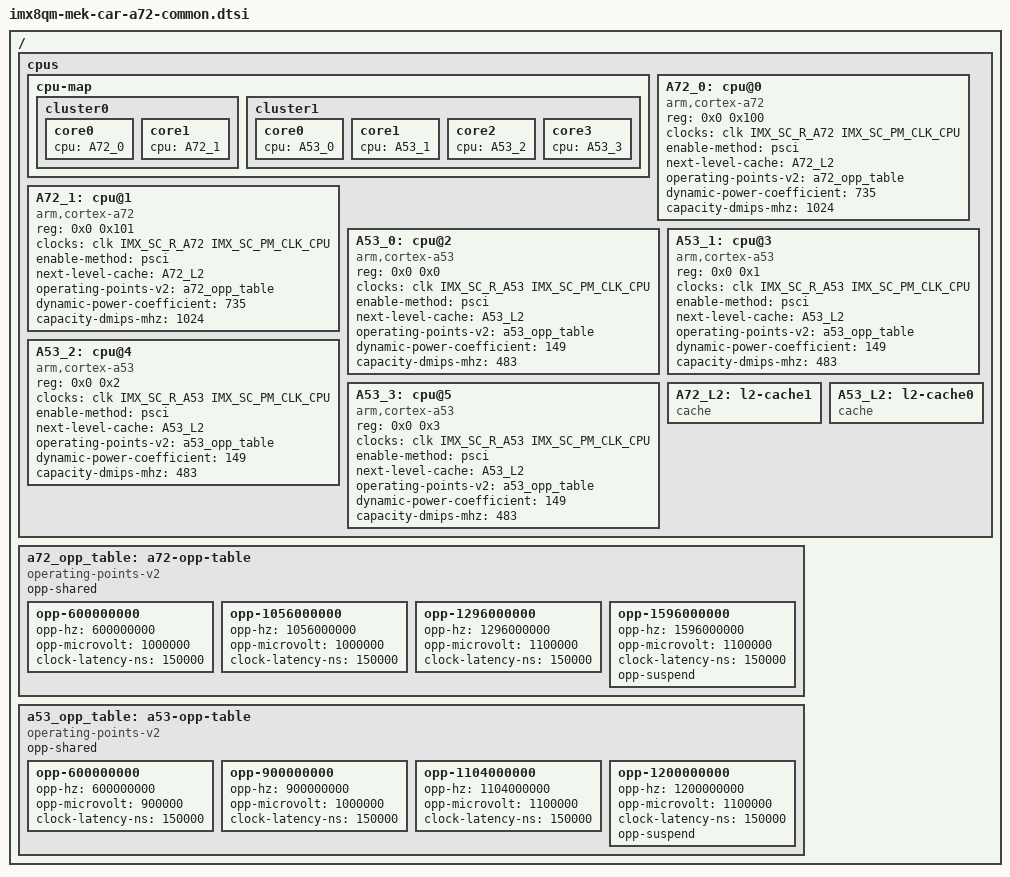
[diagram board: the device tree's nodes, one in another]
/*
 * Copyright 2020 NXP
 *
 * This program is free software; you can redistribute it and/or
 * modify it under the terms of the GNU General Public License
 * as published by the Free Software Foundation; either version 2
 * of the License, or (at your option) any later version.
 *
 * This program is distributed in the hope that it will be useful,
 * but WITHOUT ANY WARRANTY; without even the implied warranty of
 * MERCHANTABILITY or FITNESS FOR A PARTICULAR PURPOSE.  See the
 * GNU General Public License for more details.
 */

/ {
    /delete-node/ cpus;
};

/* copied from imx8qm.dtsi */
/ {
	cpus: cpus {
		#address-cells = <2>;
		#size-cells = <0>;

		cpu-map {
			cluster0 {
				core0 {
					cpu = <&A72_0>;
				};
				core1 {
					cpu = <&A72_1>;
				};
			};

			cluster1 {
				core0 {
					cpu = <&A53_0>;
				};
				core1 {
					cpu = <&A53_1>;
				};
				core2 {
					cpu = <&A53_2>;
				};
				core3 {
					cpu = <&A53_3>;
				};
			};
		};

		A72_0: cpu@0 {
			device_type = "cpu";
			compatible = "arm,cortex-a72", "arm,armv8";
			reg = <0x0 0x100>;
			clocks = <&clk IMX_SC_R_A72 IMX_SC_PM_CLK_CPU>;
			enable-method = "psci";
			next-level-cache = <&A72_L2>;
			operating-points-v2 = <&a72_opp_table>;
			#cooling-cells = <2>;
			dynamic-power-coefficient = <735>;
			capacity-dmips-mhz = <1024>;
		};

		A72_1: cpu@1 {
			device_type = "cpu";
			compatible = "arm,cortex-a72", "arm,armv8";
			reg = <0x0 0x101>;
			clocks = <&clk IMX_SC_R_A72 IMX_SC_PM_CLK_CPU>;
			enable-method = "psci";
			next-level-cache = <&A72_L2>;
			operating-points-v2 = <&a72_opp_table>;
			#cooling-cells = <2>;
			dynamic-power-coefficient = <735>;
			capacity-dmips-mhz = <1024>;
		};

		A53_0: cpu@2 {
			device_type = "cpu";
			compatible = "arm,cortex-a53", "arm,armv8";
			reg = <0x0 0x0>;
			clocks = <&clk IMX_SC_R_A53 IMX_SC_PM_CLK_CPU>;
			enable-method = "psci";
			next-level-cache = <&A53_L2>;
			operating-points-v2 = <&a53_opp_table>;
			#cooling-cells = <2>;
			dynamic-power-coefficient = <149>;
			capacity-dmips-mhz = <483>;
		};

		A53_1: cpu@3 {
			device_type = "cpu";
			compatible = "arm,cortex-a53", "arm,armv8";
			reg = <0x0 0x1>;
			clocks = <&clk IMX_SC_R_A53 IMX_SC_PM_CLK_CPU>;
			enable-method = "psci";
			next-level-cache = <&A53_L2>;
			operating-points-v2 = <&a53_opp_table>;
			#cooling-cells = <2>;
			dynamic-power-coefficient = <149>;
			capacity-dmips-mhz = <483>;
		};

		A53_2: cpu@4 {
			device_type = "cpu";
			compatible = "arm,cortex-a53", "arm,armv8";
			reg = <0x0 0x2>;
			clocks = <&clk IMX_SC_R_A53 IMX_SC_PM_CLK_CPU>;
			enable-method = "psci";
			next-level-cache = <&A53_L2>;
			operating-points-v2 = <&a53_opp_table>;
			#cooling-cells = <2>;
			dynamic-power-coefficient = <149>;
			capacity-dmips-mhz = <483>;
		};

		A53_3: cpu@5 {
			device_type = "cpu";
			compatible = "arm,cortex-a53", "arm,armv8";
			reg = <0x0 0x3>;
			clocks = <&clk IMX_SC_R_A53 IMX_SC_PM_CLK_CPU>;
			enable-method = "psci";
			next-level-cache = <&A53_L2>;
			operating-points-v2 = <&a53_opp_table>;
			#cooling-cells = <2>;
			dynamic-power-coefficient = <149>;
			capacity-dmips-mhz = <483>;
		};

		A72_L2: l2-cache1 {
			compatible = "cache";
		};

		A53_L2: l2-cache0 {
			compatible = "cache";
		};
	};

	a72_opp_table: a72-opp-table {
		compatible = "operating-points-v2";
		opp-shared;

		opp-600000000 {
			opp-hz = /bits/ 64 <600000000>;
			opp-microvolt = <1000000>;
			clock-latency-ns = <150000>;
		};

		opp-1056000000 {
			opp-hz = /bits/ 64 <1056000000>;
			opp-microvolt = <1000000>;
			clock-latency-ns = <150000>;
		};

		opp-1296000000 {
			opp-hz = /bits/ 64 <1296000000>;
			opp-microvolt = <1100000>;
			clock-latency-ns = <150000>;
		};

		opp-1596000000 {
			opp-hz = /bits/ 64 <1596000000>;
			opp-microvolt = <1100000>;
			clock-latency-ns = <150000>;
			opp-suspend;
		};
	};

	a53_opp_table: a53-opp-table {
		compatible = "operating-points-v2";
		opp-shared;

		opp-600000000 {
			opp-hz = /bits/ 64 <600000000>;
			opp-microvolt = <900000>;
			clock-latency-ns = <150000>;
		};

		opp-900000000 {
			opp-hz = /bits/ 64 <900000000>;
			opp-microvolt = <1000000>;
			clock-latency-ns = <150000>;
		};

		opp-1104000000 {
			opp-hz = /bits/ 64 <1104000000>;
			opp-microvolt = <1100000>;
			clock-latency-ns = <150000>;
		};

		opp-1200000000 {
			opp-hz = /bits/ 64 <1200000000>;
			opp-microvolt = <1100000>;
			clock-latency-ns = <150000>;
			opp-suspend;
		};
	};
};
